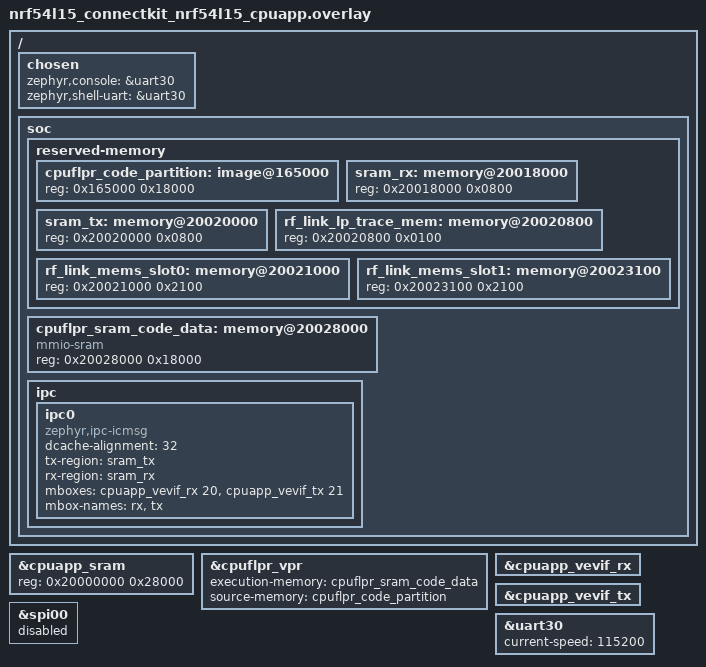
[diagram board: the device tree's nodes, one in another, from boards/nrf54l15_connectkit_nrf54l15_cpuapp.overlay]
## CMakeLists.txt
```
#
# Copyright (c) 2018 Nordic Semiconductor
# Copyright (c) 2016-2025 Makerdiary <https://makerdiary.com>
#
# SPDX-License-Identifier: LicenseRef-Nordic-5-Clause
#
cmake_minimum_required(VERSION 3.20.0)

find_package(Zephyr REQUIRED HINTS $ENV{ZEPHYR_BASE})
project(rf_link_tx)

# NORDIC SDK APP START
target_sources(app PRIVATE
  src/fatal_diag.c
  src/main.c
  src/debug_uart.c
  src/ipc_bridge.c
  src/radio_link.c
)

target_include_directories(app PRIVATE
  src
  ${CMAKE_CURRENT_SOURCE_DIR}/../rf_link_common
)

# NORDIC SDK APP END
```

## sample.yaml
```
sample:
  name: RF Link TX
tests:
  application.rf_link_tx:
    sysbuild: true
    build_only: true
    integration_platforms:
      - nrf54l15_connectkit/nrf54l15/cpuapp
```

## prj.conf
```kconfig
CONFIG_SERIAL=y
CONFIG_CONSOLE=y
CONFIG_UART_CONSOLE=n

CONFIG_MBOX=y
CONFIG_IPC_SERVICE=y
CONFIG_IPC_SERVICE_BACKEND_ICMSG=y
CONFIG_ASSERT=y
CONFIG_CRC=y

CONFIG_ESB=y
CONFIG_ESB_MAX_PAYLOAD_LENGTH=224
CONFIG_ESB_TX_FIFO_SIZE=16
CONFIG_ESB_RX_FIFO_SIZE=16
CONFIG_CLOCK_CONTROL=y
CONFIG_NRFX_DPPI10=y

CONFIG_MAIN_STACK_SIZE=4096
CONFIG_IPC_SERVICE_BACKEND_ICMSG_WQ_STACK_SIZE=4096
CONFIG_PBUF_RX_READ_BUF_SIZE=256
```

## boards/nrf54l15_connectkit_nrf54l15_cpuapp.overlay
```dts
/ {
	chosen {
		zephyr,console = &uart30;
		zephyr,shell-uart = &uart30;
	};

	soc {
		reserved-memory {
			#address-cells = <1>;
			#size-cells = <1>;
			ranges;

			/* FLPR code partition */
			cpuflpr_code_partition: image@165000 {
				reg = <0x165000 0x18000>; /* 96 KB */
			};

			/* ICMSG shared memory: HP receives here */
			sram_rx: memory@20018000 {
				reg = <0x20018000 0x0800>;
			};

			/* ICMSG shared memory: HP transmits here */
			sram_tx: memory@20020000 {
				reg = <0x20020000 0x0800>;
			};

			/* LP runtime trace shared with HP for diagnostics */
			rf_link_lp_trace_mem: memory@20020800 {
				reg = <0x20020800 0x0100>;
			};

			/* Ping-pong MEMS batches written by FLPR and read by CPUAPP. */
			rf_link_mems_slot0: memory@20021000 {
				reg = <0x20021000 0x2100>;
			};

			rf_link_mems_slot1: memory@20023100 {
				reg = <0x20023100 0x2100>;
			};
		};

		/* FLPR execution SRAM */
		cpuflpr_sram_code_data: memory@20028000 {
			compatible = "mmio-sram";
			reg = <0x20028000 0x18000>; /* 96 KB */
			#address-cells = <1>;
			#size-cells = <1>;
			ranges = <0x0 0x20028000 0x18000>;
		};

		ipc {
			ipc0: ipc0 {
				compatible = "zephyr,ipc-icmsg";
				dcache-alignment = <32>;
				tx-region = <&sram_tx>;
				rx-region = <&sram_rx>;
				mboxes = <&cpuapp_vevif_rx 20>, <&cpuapp_vevif_tx 21>;
				mbox-names = "rx", "tx";
				status = "okay";
			};
		};
	};
};

&cpuapp_sram {
	reg = <0x20000000 0x28000>; /* 160 KB */
	ranges = <0x0 0x20000000 0x28000>;
};

&cpuflpr_vpr {
	status = "okay";
	execution-memory = <&cpuflpr_sram_code_data>;
	source-memory = <&cpuflpr_code_partition>;
};

&cpuapp_vevif_rx {
	status = "okay";
};

&cpuapp_vevif_tx {
	status = "okay";
};

/* SPIM00 is owned by FLPR while it acquires IIM-42352 samples. */
&spi00 {
	status = "disabled";
};

&uart30 {
	status = "okay";
	current-speed = <115200>;
	/delete-property/ hw-flow-control;
};
```

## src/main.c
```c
#include <errno.h>
#include <stdint.h>
#include <string.h>
#include <zephyr/cache.h>
#include <zephyr/app_version.h>
#include <zephyr/kernel.h>
#include <zephyr/sys/barrier.h>
#include <zephyr/sys/crc.h>

#include "debug_uart.h"
#include "ipc_bridge.h"
#include "lp_trace.h"
#include "mems_batch.h"
#include "radio_link.h"
#include "rf_link_proto.h"

#define BATCH_RELEASE_TIMEOUT_MS 20u
#define BATCH_RELEASE_RETRIES    3u

struct batch_tx_stats {
	uint32_t batches_received;
	uint32_t batches_sent;
	uint32_t batches_failed;
	uint32_t batch_bad_header;
	uint32_t batch_bad_crc;
	uint32_t frames_attempted;
	uint32_t frames_sent;
	uint32_t frames_failed;
	uint32_t samples_sent;
	uint32_t release_errors;
};

static struct batch_tx_stats batch_stats;
static uint16_t rf_seq;
static bool radio_ready;

static void print_boot_line(void)
{
	debug_uart_puts("\r\nrf_link_tx HP started");
	debug_uart_crlf();
	debug_uart_puts("mode=MEMS_BATCH_ESB_PTX,phy=");
	debug_uart_puts(radio_link_phy_label());
	debug_uart_puts(",ack=");
	debug_uart_puts(RF_LINK_NOACK_STREAM ? "noack" : "ack");
	debug_uart_puts(",channel=");
	debug_uart_u32(RF_LINK_CHANNEL);
	debug_uart_puts(",pipe=");
	debug_uart_u32(RF_LINK_PIPE);
	debug_uart_puts(",prefix=0x54,fw=");
	debug_uart_puts(STRINGIFY(APP_BUILD_VERSION));
	debug_uart_puts(",batch_samples=");
	debug_uart_u32(RF_LINK_MEMS_BATCH_SAMPLE_COUNT);
	debug_uart_puts(",samples_per_frame=");
	debug_uart_u32(RF_LINK_FRAME_SAMPLE_COUNT);
	debug_uart_puts(",sample_hz=");
	debug_uart_u32(RF_LINK_TARGET_SAMPLE_HZ);
	debug_uart_crlf();
}

static void print_status(void)
{
	struct ipc_bridge_stats ipc_stats;
	struct rf_link_lp_trace lp_trace;
	struct radio_link_stats radio_stats = {0};
	bool have_lp_trace;

	ipc_bridge_stats_get(&ipc_stats);
	if (radio_ready) {
		radio_link_stats_get(&radio_stats);
	}
	have_lp_trace = rf_link_lp_trace_snapshot(&lp_trace);

	debug_uart_puts("TX stat batches_rx=");
	debug_uart_u32(batch_stats.batches_received);
	debug_uart_puts(" batches_ok=");
	debug_uart_u32(batch_stats.batches_sent);
	debug_uart_puts(" batch_bad_hdr=");
	debug_uart_u32(batch_stats.batch_bad_header);
	debug_uart_puts(" batches_fail=");
	debug_uart_u32(batch_stats.batches_failed);
	debug_uart_puts(" batch_bad_crc=");
	debug_uart_u32(batch_stats.batch_bad_crc);
	debug_uart_puts(" frames_try=");
	debug_uart_u32(batch_stats.frames_attempted);
	debug_uart_puts(" frames_ok=");
	debug_uart_u32(batch_stats.frames_sent);
	debug_uart_puts(" frames_fail=");
	debug_uart_u32(batch_stats.frames_failed);
	debug_uart_puts(" samples_ok=");
	debug_uart_u32(batch_stats.samples_sent);
	debug_uart_puts(" ipc_bad=");
	debug_uart_u32(ipc_stats.bad_size + ipc_stats.bad_message);
	debug_uart_puts(" ipc_drop=");
	debug_uart_u32(ipc_stats.queue_drop);
	debug_uart_puts(" release_err=");
	debug_uart_u32(batch_stats.release_errors + ipc_stats.release_fail);
	debug_uart_puts(" rf_ok=");
	debug_uart_u32(radio_stats.tx_ok);
	debug_uart_puts(" rf_fail=");
	debug_uart_u32(radio_stats.tx_failed);
	debug_uart_puts(" rf_timeout=");
	debug_uart_u32(radio_stats.tx_timeout);
	debug_uart_puts(" mac_avg_us=");
	debug_uart_u32(radio_stats.mac_latency_avg_us);
	debug_uart_puts(" lp_stage=");
	debug_uart_u32(have_lp_trace ? lp_trace.stage : 0u);
	debug_uart_puts(" lp_batches=");
	debug_uart_u32(have_lp_trace ? lp_trace.batches_ready : 0u);
	debug_uart_puts(" lp_samples=");
	debug_uart_u32(have_lp_trace ? lp_trace.sensor_samples : 0u);
	debug_uart_puts(" lp_irq=");
	debug_uart_u32(have_lp_trace ? lp_trace.sensor_irq_count : 0u);
	debug_uart_puts(" lp_poll=");
	debug_uart_u32(have_lp_trace ? lp_trace.sensor_poll_fallbacks : 0u);
	debug_uart_puts(" lp_malformed=");
	debug_uart_u32(have_lp_trace ? lp_trace.sensor_malformed : 0u);
	debug_uart_puts(" lp_io_err=");
	debug_uart_u32(have_lp_trace ? lp_trace.sensor_io_errors : 0u);
	debug_uart_puts(" lp_fifo_ovf=");
	debug_uart_u32(have_lp_trace ? lp_trace.fifo_overflows : 0u);
	debug_uart_puts(" lp_slot_wait=");
	debug_uart_u32(have_lp_trace ? lp_trace.slot_waits : 0u);
	debug_uart_puts(" lp_fatal=");
	debug_uart_u32(have_lp_trace ? lp_trace.fatal_count : 0u);
	debug_uart_puts(" lp_fatal_reason=");
	debug_uart_u32(have_lp_trace ? lp_trace.fatal_reason : 0u);
	debug_uart_crlf();
}

static int ensure_radio_ready(void)
{
	int ret;

	if (radio_ready) {
		return 0;
	}

	ret = radio_link_init();
	if (ret == 0) {
		radio_ready = true;
		debug_uart_puts("radio ready after first MEMS batch");
		debug_uart_crlf();
	}

	return ret;
}

static bool batch_header_is_valid(
	const volatile struct rf_link_mems_batch *batch,
	const struct rf_link_ipc_message *message)
{
	return batch != NULL && message != NULL &&
	       batch->magic == RF_LINK_MEMS_BATCH_MAGIC &&
	       batch->version == RF_LINK_MEMS_BATCH_VERSION &&
	       batch->slot_index == message->slot_index &&
	       batch->batch_seq == message->batch_seq &&
	       batch->sample_count == RF_LINK_MEMS_BATCH_SAMPLE_COUNT &&
	       batch->sample_crc32 == message->sample_crc32;
}

static int transmit_batch(const struct rf_link_ipc_message *message)
{
	volatile struct rf_link_mems_batch *batch;
	const int16_t *samples;
	uint32_t crc;
	uint32_t offset = 0u;
	int first_error = 0;
	int ret;

	batch = rf_link_mems_batch_slot(message->slot_index);
	if (batch == NULL) {
		batch_stats.batch_bad_header++;
		return -EINVAL;
	}

	(void)sys_cache_data_invd_range((void *)(uintptr_t)batch, sizeof(*batch));
	barrier_dmem_fence_full();
	batch_stats.batches_received++;

	if (!batch_header_is_valid(batch, message)) {
		batch_stats.batch_bad_header++;
		return -EBADMSG;
	}

	samples = (const int16_t *)(uintptr_t)&batch->samples[0];
	crc = crc32_ieee((const uint8_t *)samples, sizeof(batch->samples));
	if (crc != message->sample_crc32) {
		batch_stats.batch_bad_crc++;
		return -EBADMSG;
	}

	ret = ensure_radio_ready();
	if (ret != 0) {
		return ret;
	}

	while (offset < RF_LINK_MEMS_BATCH_SAMPLE_COUNT) {
		struct rf_frame frame = {0};
		uint32_t remaining = RF_LINK_MEMS_BATCH_SAMPLE_COUNT - offset;
		uint32_t frame_samples = MIN(remaining, RF_LINK_FRAME_SAMPLE_COUNT);

		frame.magic = RF_LINK_MAGIC;
		frame.seq = rf_seq++;
		frame.sample_count = (uint16_t)frame_samples;
		frame.flags = RF_LINK_FRAME_FLAGS_MEMS;
		if (offset == 0u) {
			frame.flags |= RF_LINK_FRAME_FLAGS_BATCH_START;
		}
		if (frame_samples == remaining) {
			frame.flags |= RF_LINK_FRAME_FLAGS_BATCH_END;
		}
		frame.timestamp_ms = batch->capture_start_ms +
			(uint32_t)(((uint64_t)offset * 1000u) /
				   RF_LINK_TARGET_SAMPLE_HZ);
		memcpy(frame.samples, &samples[offset],
		       frame_samples * sizeof(frame.samples[0]));

		batch_stats.frames_attempted++;
		ret = radio_link_send_frame(&frame, K_MSEC(5));
		if (ret == 0) {
			batch_stats.frames_sent++;
			batch_stats.samples_sent += frame_samples;
		} else {
			batch_stats.frames_failed++;
			if (first_error == 0) {
				first_error = ret;
			}
		}
		offset += frame_samples;
	}

	if (first_error == 0) {
		batch_stats.batches_sent++;
	} else {
		batch_stats.batches_failed++;
	}

	return first_error;
}

static void release_batch(const struct rf_link_ipc_message *message)
{
	int ret = -EIO;

	for (uint32_t attempt = 0u; attempt < BATCH_RELEASE_RETRIES; attempt++) {
		ret = ipc_bridge_release_batch(message->slot_index, message->batch_seq,
					       K_MSEC(BATCH_RELEASE_TIMEOUT_MS));
		if (ret == 0) {
			return;
		}
	}

	batch_stats.release_errors++;
}

int main(void)
{
	struct rf_link_ipc_message message;
	uint32_t last_status_ms;
	int ret;

	(void)debug_uart_init();
	print_boot_line();
	memset(&batch_stats, 0, sizeof(batch_stats));
	rf_seq = 0u;
	radio_ready = false;

	ret = ipc_bridge_init();
	if (ret != 0) {
		debug_uart_puts("ipc init failed err=");
		debug_uart_i32(ret);
		debug_uart_crlf();
		return ret;
	}

	ret = ipc_bridge_wait_bound(K_FOREVER);
	if (ret != 0) {
		debug_uart_puts("ipc bind failed err=");
		debug_uart_i32(ret);
		debug_uart_crlf();
		return ret;
	}

	debug_uart_puts("LP IPC bound; CPUAPP blocking until a 4096-sample batch is ready");
	debug_uart_crlf();
	last_status_ms = k_uptime_get_32();

	while (1) {
		ret = ipc_bridge_wait_batch(&message, K_FOREVER);
		if (ret != 0) {
			continue;
		}

		ret = transmit_batch(&message);
		if (ret != 0) {
			debug_uart_puts("batch rejected/failed seq=");
			debug_uart_u32(message.batch_seq);
			debug_uart_puts(" err=");
			debug_uart_i32(ret);
			debug_uart_crlf();
		}
		release_batch(&message);

		if ((uint32_t)(k_uptime_get_32() - last_status_ms) >=
		    RF_LINK_STATUS_PERIOD_MS) {
			print_status();
			last_status_ms = k_uptime_get_32();
		}
	}
}
```

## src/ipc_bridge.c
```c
#include "ipc_bridge.h"

#include <errno.h>
#include <string.h>
#include <zephyr/device.h>
#include <zephyr/devicetree.h>
#include <zephyr/ipc/ipc_service.h>
#include <zephyr/sys/atomic.h>

#define IPC_NODE DT_NODELABEL(ipc0)

#if !DT_NODE_HAS_STATUS(IPC_NODE, okay)
#error "ipc0 is not enabled in devicetree"
#endif

static K_SEM_DEFINE(bound_sem, 0, 1);
K_MSGQ_DEFINE(batch_msgq, sizeof(struct rf_link_ipc_message),
	      RF_LINK_MEMS_BATCH_SLOT_COUNT, 4);

static struct ipc_ept hp_ept;
static atomic_t received;
static atomic_t bad_size;
static atomic_t bad_message;
static atomic_t queued;
static atomic_t queue_drop;
static atomic_t releases;
static atomic_t release_fail;

static void bridge_bound(void *priv)
{
	ARG_UNUSED(priv);
	k_sem_give(&bound_sem);
}

static void bridge_received(const void *data, size_t len, void *priv)
{
	struct rf_link_ipc_message message;
	int ret;

	ARG_UNUSED(priv);
	atomic_inc(&received);

	if (data == NULL || len != sizeof(message)) {
		atomic_inc(&bad_size);
		return;
	}

	memcpy(&message, data, sizeof(message));
	if (message.magic != RF_LINK_IPC_MAGIC ||
	    message.version != RF_LINK_IPC_VERSION ||
	    message.type != RF_LINK_IPC_BATCH_READY ||
	    message.slot_index >= RF_LINK_MEMS_BATCH_SLOT_COUNT ||
	    message.sample_count != RF_LINK_MEMS_BATCH_SAMPLE_COUNT) {
		atomic_inc(&bad_message);
		return;
	}

	ret = k_msgq_put(&batch_msgq, &message, K_NO_WAIT);
	if (ret == 0) {
		atomic_inc(&queued);
	} else {
		atomic_inc(&queue_drop);
	}
}

static void bridge_error(const char *message, void *priv)
{
	ARG_UNUSED(message);
	ARG_UNUSED(priv);
}

static const struct ipc_ept_cfg hp_ept_cfg = {
	.name = "rf_link_ept",
	.cb = {
		.bound = bridge_bound,
		.received = bridge_received,
		.error = bridge_error,
	},
};

int ipc_bridge_init(void)
{
	const struct device *ipc0 = DEVICE_DT_GET(IPC_NODE);
	int ret;

	if (!device_is_ready(ipc0)) {
		return -ENODEV;
	}

	k_msgq_purge(&batch_msgq);
	atomic_clear(&received);
	atomic_clear(&bad_size);
	atomic_clear(&bad_message);
	atomic_clear(&queued);
	atomic_clear(&queue_drop);
	atomic_clear(&releases);
	atomic_clear(&release_fail);

	ret = ipc_service_open_instance(ipc0);
	if (ret < 0 && ret != -EALREADY) {
		return ret;
	}

	return ipc_service_register_endpoint(ipc0, &hp_ept, &hp_ept_cfg);
}

int ipc_bridge_wait_bound(k_timeout_t timeout)
{
	return k_sem_take(&bound_sem, timeout);
}

int ipc_bridge_wait_batch(struct rf_link_ipc_message *message,
			  k_timeout_t timeout)
{
	if (message == NULL) {
		return -EINVAL;
	}

	return k_msgq_get(&batch_msgq, message, timeout);
}

int ipc_bridge_release_batch(uint32_t slot_index, uint32_t batch_seq,
			     k_timeout_t timeout)
{
	struct rf_link_ipc_message message = {
		.magic = RF_LINK_IPC_MAGIC,
		.version = RF_LINK_IPC_VERSION,
		.type = RF_LINK_IPC_BATCH_RELEASE,
		.slot_index = slot_index,
		.batch_seq = batch_seq,
	};
	k_timepoint_t end = sys_timepoint_calc(timeout);
	int ret;

	do {
		ret = ipc_service_send(&hp_ept, &message, sizeof(message));
		if (ret == 0 || ret == (int)sizeof(message)) {
			atomic_inc(&releases);
			return 0;
		}

		if (ret != -ENOMEM && ret != -EAGAIN &&
		    ret != -EBUSY && ret != -ENOBUFS) {
			break;
		}
		k_sleep(K_USEC(50));
	} while (K_TIMEOUT_EQ(timeout, K_FOREVER) || !sys_timepoint_expired(end));

	atomic_inc(&release_fail);
	return ret;
}

void ipc_bridge_stats_get(struct ipc_bridge_stats *stats)
{
	if (stats == NULL) {
		return;
	}

	stats->received = (uint32_t)atomic_get(&received);
	stats->bad_size = (uint32_t)atomic_get(&bad_size);
	stats->bad_message = (uint32_t)atomic_get(&bad_message);
	stats->queued = (uint32_t)atomic_get(&queued);
	stats->queue_drop = (uint32_t)atomic_get(&queue_drop);
	stats->releases = (uint32_t)atomic_get(&releases);
	stats->release_fail = (uint32_t)atomic_get(&release_fail);
}
```

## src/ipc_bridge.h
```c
#ifndef RF_LINK_IPC_BRIDGE_H_
#define RF_LINK_IPC_BRIDGE_H_

#include <stdint.h>
#include <zephyr/kernel.h>

#include "mems_batch.h"

struct ipc_bridge_stats {
	uint32_t received;
	uint32_t bad_size;
	uint32_t bad_message;
	uint32_t queued;
	uint32_t queue_drop;
	uint32_t releases;
	uint32_t release_fail;
};

int ipc_bridge_init(void);
int ipc_bridge_wait_bound(k_timeout_t timeout);
int ipc_bridge_wait_batch(struct rf_link_ipc_message *message,
			  k_timeout_t timeout);
int ipc_bridge_release_batch(uint32_t slot_index, uint32_t batch_seq,
			     k_timeout_t timeout);
void ipc_bridge_stats_get(struct ipc_bridge_stats *stats);

#endif /* RF_LINK_IPC_BRIDGE_H_ */
```

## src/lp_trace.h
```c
#ifndef RF_LINK_LP_TRACE_H_
#define RF_LINK_LP_TRACE_H_

#include <stdbool.h>
#include <stdint.h>
#include <zephyr/devicetree.h>
#include <zephyr/kernel.h>

#define RF_LINK_LP_TRACE_MAGIC   0x4c505452u
#define RF_LINK_LP_TRACE_VERSION 1u             //默认是 deadline 模式，要改回相对 k_sleep() 版本置0

#define RF_LINK_LP_TRACE_NODE DT_NODELABEL(rf_link_lp_trace_mem)

#if !DT_NODE_HAS_STATUS(RF_LINK_LP_TRACE_NODE, okay)
#error "rf_link_lp_trace_mem is not enabled in devicetree"
#endif

enum rf_link_lp_stage {
	RF_LINK_LP_STAGE_RESET = 0u,
	RF_LINK_LP_STAGE_BOOT = 1u,
	RF_LINK_LP_STAGE_IPC_READY = 2u,
	RF_LINK_LP_STAGE_IPC_BOUND = 3u,
	RF_LINK_LP_STAGE_RUN = 4u,
};

struct rf_link_lp_trace {
	uint32_t magic;
	uint32_t version;
	uint32_t boot_count;
	uint32_t fatal_count;
	uint32_t stage;
	uint32_t loop_count;
	uint32_t last_seq;
	uint32_t last_uptime_ms;
	uint32_t fatal_reason;
	int32_t last_send_ret;
	uint32_t ipc_sent;
	uint32_t ipc_busy;
	uint32_t ipc_failed;
};

static inline volatile struct rf_link_lp_trace *rf_link_lp_trace_ptr(void)
{
	return (volatile struct rf_link_lp_trace *)(uintptr_t)
		DT_REG_ADDR(RF_LINK_LP_TRACE_NODE);
}

static inline void rf_link_lp_trace_boot(void)
{
	volatile struct rf_link_lp_trace *trace = rf_link_lp_trace_ptr();
	uint32_t boot_count = 1u;

	if (trace->magic == RF_LINK_LP_TRACE_MAGIC &&
	    trace->version == RF_LINK_LP_TRACE_VERSION) {
		boot_count = trace->boot_count + 1u;
	}

	trace->magic = RF_LINK_LP_TRACE_MAGIC;
	trace->version = RF_LINK_LP_TRACE_VERSION;
	trace->boot_count = boot_count;
	if (boot_count == 1u) {
		trace->fatal_count = 0u;
	}
	trace->stage = RF_LINK_LP_STAGE_BOOT;
	trace->loop_count = 0u;
	trace->last_seq = 0u;
	trace->last_uptime_ms = k_uptime_get_32();
	trace->fatal_reason = 0u;
	trace->last_send_ret = 0;
	trace->ipc_sent = 0u;
	trace->ipc_busy = 0u;
	trace->ipc_failed = 0u;
}

static inline void rf_link_lp_trace_set_stage(uint32_t stage)
{
	volatile struct rf_link_lp_trace *trace = rf_link_lp_trace_ptr();

	trace->stage = stage;
	trace->last_uptime_ms = k_uptime_get_32();
}

static inline void rf_link_lp_trace_note_loop(uint16_t seq)
{
	volatile struct rf_link_lp_trace *trace = rf_link_lp_trace_ptr();

	trace->stage = RF_LINK_LP_STAGE_RUN;
	trace->loop_count++;
	trace->last_seq = seq;
	trace->last_uptime_ms = k_uptime_get_32();
}

static inline void rf_link_lp_trace_note_ipc(uint32_t sent, uint32_t busy,
					     uint32_t failed, int32_t last_ret)
{
	volatile struct rf_link_lp_trace *trace = rf_link_lp_trace_ptr();

	trace->ipc_sent = sent;
	trace->ipc_busy = busy;
	trace->ipc_failed = failed;
	trace->last_send_ret = last_ret;
	trace->last_uptime_ms = k_uptime_get_32();
}

static inline void rf_link_lp_trace_note_fatal(uint32_t reason)
{
	volatile struct rf_link_lp_trace *trace = rf_link_lp_trace_ptr();

	trace->fatal_count++;
	trace->fatal_reason = reason;
	trace->last_uptime_ms = k_uptime_get_32();
}

static inline bool rf_link_lp_trace_snapshot(struct rf_link_lp_trace *out)
{
	volatile struct rf_link_lp_trace *trace = rf_link_lp_trace_ptr();

	if (out == NULL) {
		return false;
	}

	out->magic = trace->magic;
	out->version = trace->version;
	out->boot_count = trace->boot_count;
	out->fatal_count = trace->fatal_count;
	out->stage = trace->stage;
	out->loop_count = trace->loop_count;
	out->last_seq = trace->last_seq;
	out->last_uptime_ms = trace->last_uptime_ms;
	out->fatal_reason = trace->fatal_reason;
	out->last_send_ret = trace->last_send_ret;
	out->ipc_sent = trace->ipc_sent;
	out->ipc_busy = trace->ipc_busy;
	out->ipc_failed = trace->ipc_failed;

	return out->magic == RF_LINK_LP_TRACE_MAGIC &&
	       out->version == RF_LINK_LP_TRACE_VERSION;
}

#endif /* RF_LINK_LP_TRACE_H_ */
```

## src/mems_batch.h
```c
#ifndef RF_LINK_MEMS_BATCH_H_
#define RF_LINK_MEMS_BATCH_H_

#include <stddef.h>
#include <stdint.h>
#include <zephyr/devicetree.h>
#include <zephyr/sys/util.h>

#include "rf_link_proto.h"

#define RF_LINK_MEMS_BATCH_MAGIC        0x4d424154u
#define RF_LINK_MEMS_BATCH_VERSION      1u
#define RF_LINK_MEMS_BATCH_SAMPLE_COUNT 4096u
#define RF_LINK_MEMS_BATCH_SLOT_COUNT   2u

#define RF_LINK_IPC_MAGIC               0x52464950u
#define RF_LINK_IPC_VERSION             1u

enum rf_link_ipc_message_type {
	RF_LINK_IPC_BATCH_READY = 1u,
	RF_LINK_IPC_BATCH_RELEASE = 2u,
};

struct rf_link_mems_batch {
	uint32_t magic;
	uint32_t version;
	uint32_t slot_index;
	uint32_t batch_seq;
	uint32_t sample_count;
	uint32_t capture_start_ms;
	uint32_t capture_end_ms;
	uint32_t sample_crc32;
	int16_t samples[RF_LINK_MEMS_BATCH_SAMPLE_COUNT];
} __aligned(32);

struct rf_link_ipc_message {
	uint32_t magic;
	uint32_t version;
	uint32_t type;
	uint32_t slot_index;
	uint32_t batch_seq;
	uint32_t sample_count;
	uint32_t sample_crc32;
};

#define RF_LINK_MEMS_SLOT0_NODE DT_NODELABEL(rf_link_mems_slot0)
#define RF_LINK_MEMS_SLOT1_NODE DT_NODELABEL(rf_link_mems_slot1)

#if !DT_NODE_HAS_STATUS(RF_LINK_MEMS_SLOT0_NODE, okay)
#error "rf_link_mems_slot0 is not enabled in devicetree"
#endif

#if !DT_NODE_HAS_STATUS(RF_LINK_MEMS_SLOT1_NODE, okay)
#error "rf_link_mems_slot1 is not enabled in devicetree"
#endif

BUILD_ASSERT(RF_LINK_MEMS_BATCH_SAMPLE_COUNT > RF_LINK_FRAME_SAMPLE_COUNT,
	     "MEMS batch must contain more than one radio frame");
BUILD_ASSERT(DT_REG_SIZE(RF_LINK_MEMS_SLOT0_NODE) >= sizeof(struct rf_link_mems_batch),
	     "MEMS shared slot 0 is too small");
BUILD_ASSERT(DT_REG_SIZE(RF_LINK_MEMS_SLOT1_NODE) >= sizeof(struct rf_link_mems_batch),
	     "MEMS shared slot 1 is too small");
BUILD_ASSERT((DT_REG_ADDR(RF_LINK_MEMS_SLOT0_NODE) % 32u) == 0u,
	     "MEMS shared slot 0 must be cache-line aligned");
BUILD_ASSERT((DT_REG_ADDR(RF_LINK_MEMS_SLOT1_NODE) % 32u) == 0u,
	     "MEMS shared slot 1 must be cache-line aligned");
BUILD_ASSERT(sizeof(struct rf_link_ipc_message) <= CONFIG_PBUF_RX_READ_BUF_SIZE,
	     "PBUF RX buffer is too small for the batch IPC descriptor");

static inline volatile struct rf_link_mems_batch *rf_link_mems_batch_slot(uint32_t index)
{
	uintptr_t address;

	if (index == 0u) {
		address = DT_REG_ADDR(RF_LINK_MEMS_SLOT0_NODE);
	} else if (index == 1u) {
		address = DT_REG_ADDR(RF_LINK_MEMS_SLOT1_NODE);
	} else {
		return NULL;
	}

	return (volatile struct rf_link_mems_batch *)address;
}

#endif /* RF_LINK_MEMS_BATCH_H_ */
```

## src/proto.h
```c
#ifndef RF_LINK_PROTO_H_
#define RF_LINK_PROTO_H_

#include <stdint.h>
#include <zephyr/sys/util.h>

#define RF_LINK_MAGIC              0xA55Au
#define RF_LINK_FRAME_SAMPLE_COUNT 96u
#define RF_LINK_FRAME_FLAGS_TEST   BIT(0)
#define RF_LINK_CHANNEL            40u
#define RF_LINK_TARGET_SAMPLE_HZ   50000u
#define RF_LINK_TX_PERIOD_US       ((RF_LINK_FRAME_SAMPLE_COUNT * 1000000u) / \
				    RF_LINK_TARGET_SAMPLE_HZ)
#define RF_LINK_STATUS_PERIOD_MS   1000u
#define RF_LINK_NOACK_STREAM       1u
#define RF_LINK_LP_START_DELAY_MS  0u
#define RF_LINK_LP_WARMUP_FRAMES   16u
#define RF_LINK_LP_WARMUP_PERIOD_MS 10u
#define RF_LINK_LP_IPC_SEND_TIMEOUT_MS 5u
#define RF_LINK_LP_USE_ABSOLUTE_PACING 1u

struct rf_frame {
	uint16_t magic;
	uint16_t seq;
	uint16_t sample_count;
	uint16_t flags;
	uint32_t timestamp_ms;
	int16_t samples[RF_LINK_FRAME_SAMPLE_COUNT];
} __packed;

#define RF_LINK_FRAME_WIRE_SIZE sizeof(struct rf_frame)

BUILD_ASSERT(RF_LINK_FRAME_WIRE_SIZE == 204u,
	     "rf_frame wire size must stay fixed for this RF protocol revision");
BUILD_ASSERT(CONFIG_PBUF_RX_READ_BUF_SIZE >= RF_LINK_FRAME_WIRE_SIZE,
	     "PBUF RX buffer must be large enough for rf_frame IPC payloads");
BUILD_ASSERT(((RF_LINK_FRAME_SAMPLE_COUNT * 1000000u) %
	      RF_LINK_TARGET_SAMPLE_HZ) == 0u,
	     "RF_LINK_TX_PERIOD_US must be an integer number of microseconds");

#endif /* RF_LINK_PROTO_H_ */
```

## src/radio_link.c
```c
#include "radio_link.h"

#include <errno.h>
#include <string.h>
#include <zephyr/device.h>
#include <zephyr/devicetree.h>
#include <zephyr/drivers/clock_control.h>
#include <zephyr/drivers/clock_control/nrf_clock_control.h>
#include <zephyr/spinlock.h>
#include <zephyr/sys/atomic.h>
#include <esb.h>
#include <nrf.h>
#include <nrf_erratas.h>

#if defined(CONFIG_CLOCK_CONTROL_NRF2)
#include <hal/nrf_lrcconf.h>
#endif

#if NRF54L_ERRATA_20_PRESENT
#include <hal/nrf_power.h>
#endif

#if defined(NRF54LM20A_ENGA_XXAA)
#include <hal/nrf_clock.h>
#endif

BUILD_ASSERT(RF_LINK_FRAME_WIRE_SIZE <= CONFIG_ESB_MAX_PAYLOAD_LENGTH,
	     "CONFIG_ESB_MAX_PAYLOAD_LENGTH is too small for rf_frame");

#if defined(RADIO_MODE_MODE_Nrf_4Mbit_0BT6)
#define RF_LINK_ESB_BITRATE ESB_BITRATE_4MBPS
#define RF_LINK_PHY_LABEL   "4M"
#else
#define RF_LINK_ESB_BITRATE ESB_BITRATE_2MBPS
#define RF_LINK_PHY_LABEL   "2M"
#endif

static K_SEM_DEFINE(tx_done_sem, 0, 1);

static atomic_t tx_ok;
static atomic_t tx_failed;
static atomic_t tx_timeout;
static atomic_t tx_errors;
static atomic_t last_attempts;
static volatile int last_tx_result;

static struct k_spinlock latency_lock;
static uint32_t latency_count;
static uint32_t latency_last_us;
static uint32_t latency_min_us = UINT32_MAX;
static uint32_t latency_max_us;
static uint64_t latency_sum_us;

static void latency_stats_update(uint32_t latency_us)
{
	k_spinlock_key_t key = k_spin_lock(&latency_lock);

	latency_last_us = latency_us;
	if (latency_us < latency_min_us) {
		latency_min_us = latency_us;
	}
	if (latency_us > latency_max_us) {
		latency_max_us = latency_us;
	}
	latency_sum_us += latency_us;
	latency_count++;

	k_spin_unlock(&latency_lock, key);
}

static void radio_event_handler(const struct esb_evt *event)
{
	switch (event->evt_id) {
	case ESB_EVENT_TX_SUCCESS:
		last_tx_result = 0;
		atomic_inc(&tx_ok);
		atomic_set(&last_attempts, (atomic_val_t)event->tx_attempts);
		k_sem_give(&tx_done_sem);
		break;
	case ESB_EVENT_TX_FAILED:
		last_tx_result = -EIO;
		atomic_inc(&tx_failed);
		atomic_set(&last_attempts, (atomic_val_t)event->tx_attempts);
		k_sem_give(&tx_done_sem);
		break;
	case ESB_EVENT_RX_RECEIVED:
		break;
	}
}

#if defined(CONFIG_CLOCK_CONTROL_NRF)
static int clocks_start(void)
{
	int err;
	int res;
	struct onoff_manager *clk_mgr;
	struct onoff_client clk_cli;

	clk_mgr = z_nrf_clock_control_get_onoff(CLOCK_CONTROL_NRF_SUBSYS_HF);
	if (clk_mgr == NULL) {
		return -ENXIO;
	}

	sys_notify_init_spinwait(&clk_cli.notify);

	err = onoff_request(clk_mgr, &clk_cli);
	if (err < 0) {
		return err;
	}

	do {
		err = sys_notify_fetch_result(&clk_cli.notify, &res);
		if (err == 0 && res != 0) {
			return res;
		}
	} while (err != 0);

#if NRF54L_ERRATA_20_PRESENT
	if (nrf54l_errata_20()) {
		nrf_power_task_trigger(NRF_POWER, NRF_POWER_TASK_CONSTLAT);
	}
#endif

#if defined(NRF54LM20A_ENGA_XXAA)
	nrf_clock_task_trigger(NRF_CLOCK, NRF_CLOCK_TASK_PLLSTART);
#endif

	return 0;
}
#elif defined(CONFIG_CLOCK_CONTROL_NRF2)
static int clocks_start(void)
{
	int err;
	int res;
	const struct device *radio_clk_dev =
		DEVICE_DT_GET_OR_NULL(DT_CLOCKS_CTLR(DT_NODELABEL(radio)));
	struct onoff_client radio_cli;

	if (radio_clk_dev == NULL) {
		return -ENODEV;
	}

	nrf_lrcconf_poweron_force_set(NRF_LRCCONF010,
				      NRF_LRCCONF_POWER_DOMAIN_1, true);
	sys_notify_init_spinwait(&radio_cli.notify);

	err = nrf_clock_control_request(radio_clk_dev, NULL, &radio_cli);
	if (err < 0 && err != -EALREADY) {
		return err;
	}

	do {
		err = sys_notify_fetch_result(&radio_cli.notify, &res);
		if (err == 0 && res != 0) {
			return res;
		}
	} while (err == -EAGAIN);

	nrf_lrcconf_clock_always_run_force_set(NRF_LRCCONF000, 0, true);
	nrf_lrcconf_task_trigger(NRF_LRCCONF000, NRF_LRCCONF_TASK_CLKSTART_0);

	return 0;
}
#else
BUILD_ASSERT(false, "No Nordic clock control driver enabled");
#endif

int radio_link_init(void)
{
	static const uint8_t base_addr_0[4] = {0x52, 0x46, 0x4c, 0x31};
	static const uint8_t base_addr_1[4] = {0xc2, 0xc2, 0xc2, 0xc2};
	static const uint8_t addr_prefix[8] = {
		0x54, 0xc2, 0xc3, 0xc4, 0xc5, 0xc6, 0xc7, 0xc8
	};
	struct esb_config config = ESB_DEFAULT_CONFIG;
	int ret;

	ret = clocks_start();
	if (ret != 0) {
		return ret;
	}

	config.protocol = ESB_PROTOCOL_ESB_DPL;
	config.mode = ESB_MODE_PTX;
	config.bitrate = RF_LINK_ESB_BITRATE;
	config.crc = ESB_CRC_16BIT;
	config.event_handler = radio_event_handler;
	config.retransmit_delay = 600;
	config.retransmit_count = 0;
	config.payload_length = RF_LINK_FRAME_WIRE_SIZE;
	config.selective_auto_ack = true;
	config.tx_mode = ESB_TXMODE_AUTO;

	ret = esb_init(&config);
	if (ret != 0) {
		return ret;
	}

	ret = esb_set_address_length(5);
	if (ret != 0) {
		return ret;
	}

	ret = esb_set_base_address_0(base_addr_0);
	if (ret != 0) {
		return ret;
	}

	ret = esb_set_base_address_1(base_addr_1);
	if (ret != 0) {
		return ret;
	}

	ret = esb_set_prefixes(addr_prefix, ARRAY_SIZE(addr_prefix));
	if (ret != 0) {
		return ret;
	}

	ret = esb_set_rf_channel(RF_LINK_CHANNEL);
	if (ret != 0) {
		return ret;
	}

	return esb_flush_tx();
}

int radio_link_send_frame(const struct rf_frame *frame, k_timeout_t timeout)
{
	struct esb_payload payload = {0};
	uint32_t start_cycles;
	uint32_t elapsed_cycles;
	int ret;

	if (frame == NULL) {
		return -EINVAL;
	}

	payload.pipe = 0;
	payload.noack = RF_LINK_NOACK_STREAM ? true : false;
	payload.length = RF_LINK_FRAME_WIRE_SIZE;
	memcpy(payload.data, frame, sizeof(*frame));

	k_sem_reset(&tx_done_sem);
	last_tx_result = -EINPROGRESS;

	start_cycles = k_cycle_get_32();

	ret = esb_write_payload(&payload);
	if (ret != 0) {
		atomic_inc(&tx_errors);
		return ret;
	}

	ret = k_sem_take(&tx_done_sem, timeout);
	elapsed_cycles = k_cycle_get_32() - start_cycles;
	latency_stats_update(k_cyc_to_us_floor32(elapsed_cycles));

	if (ret != 0) {
		atomic_inc(&tx_timeout);
		(void)esb_flush_tx();
		return -ETIMEDOUT;
	}

	return last_tx_result;
}

void radio_link_stats_get(struct radio_link_stats *stats)
{
	k_spinlock_key_t key;

	if (stats == NULL) {
		return;
	}

	stats->tx_ok = (uint32_t)atomic_get(&tx_ok);
	stats->tx_failed = (uint32_t)atomic_get(&tx_failed);
	stats->tx_timeout = (uint32_t)atomic_get(&tx_timeout);
	stats->tx_errors = (uint32_t)atomic_get(&tx_errors);
	stats->last_attempts = (uint32_t)atomic_get(&last_attempts);

	key = k_spin_lock(&latency_lock);
	stats->mac_latency_count = latency_count;
	stats->mac_latency_last_us = latency_last_us;
	stats->mac_latency_min_us = (latency_count == 0u) ? 0u : latency_min_us;
	stats->mac_latency_avg_us = (latency_count == 0u) ? 0u :
				    (uint32_t)(latency_sum_us / latency_count);
	stats->mac_latency_max_us = latency_max_us;
	k_spin_unlock(&latency_lock, key);
}

const char *radio_link_phy_label(void)
{
	return RF_LINK_PHY_LABEL;
}
```

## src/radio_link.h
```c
#ifndef RF_LINK_RADIO_LINK_H_
#define RF_LINK_RADIO_LINK_H_

#include <stdint.h>
#include <zephyr/kernel.h>

#include "proto.h"

struct radio_link_stats {
	uint32_t tx_ok;
	uint32_t tx_failed;
	uint32_t tx_timeout;
	uint32_t tx_errors;
	uint32_t last_attempts;
	uint32_t mac_latency_count;
	uint32_t mac_latency_last_us;
	uint32_t mac_latency_min_us;
	uint32_t mac_latency_avg_us;
	uint32_t mac_latency_max_us;
};

int radio_link_init(void);
int radio_link_send_frame(const struct rf_frame *frame, k_timeout_t timeout);
void radio_link_stats_get(struct radio_link_stats *stats);
const char *radio_link_phy_label(void);

#endif /* RF_LINK_RADIO_LINK_H_ */
```

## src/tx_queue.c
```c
#include "tx_queue.h"

#include <errno.h>
#include <string.h>
#include <zephyr/sys/atomic.h>

#define TX_QUEUE_DEPTH 64

K_MSGQ_DEFINE(tx_frame_msgq, sizeof(struct rf_frame), TX_QUEUE_DEPTH, 4);

static struct rf_frame discard_frame;

static atomic_t pushed;
static atomic_t popped;
static atomic_t dropped;

void tx_queue_init(void)
{
	k_msgq_purge(&tx_frame_msgq);
	atomic_clear(&pushed);
	atomic_clear(&popped);
	atomic_clear(&dropped);
}

int tx_queue_submit(const struct rf_frame *frame)
{
	int ret;

	ret = k_msgq_put(&tx_frame_msgq, frame, K_NO_WAIT);
	if (ret == 0) {
		atomic_inc(&pushed);
		return 0;
	}

	if (ret == -ENOMSG) {
		ret = k_msgq_get(&tx_frame_msgq, &discard_frame, K_NO_WAIT);
		if (ret == 0) {
			atomic_inc(&dropped);
			ret = k_msgq_put(&tx_frame_msgq, frame, K_NO_WAIT);
			if (ret == 0) {
				atomic_inc(&pushed);
				return 0;
			}
		}
	}

	atomic_inc(&dropped);
	return ret;
}

int tx_queue_get(struct rf_frame *frame, k_timeout_t timeout)
{
	int ret = k_msgq_get(&tx_frame_msgq, frame, timeout);

	if (ret == 0) {
		atomic_inc(&popped);
	}

	return ret;
}

void tx_queue_stats_get(struct tx_queue_stats *stats)
{
	if (stats == NULL) {
		return;
	}

	stats->pushed = (uint32_t)atomic_get(&pushed);
	stats->popped = (uint32_t)atomic_get(&popped);
	stats->dropped = (uint32_t)atomic_get(&dropped);
}
```

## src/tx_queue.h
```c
#ifndef RF_LINK_TX_QUEUE_H_
#define RF_LINK_TX_QUEUE_H_

#include <stdint.h>
#include <zephyr/kernel.h>

#include "proto.h"

struct tx_queue_stats {
	uint32_t pushed;
	uint32_t popped;
	uint32_t dropped;
};

void tx_queue_init(void);
int tx_queue_submit(const struct rf_frame *frame);
int tx_queue_get(struct rf_frame *frame, k_timeout_t timeout);
void tx_queue_stats_get(struct tx_queue_stats *stats);

#endif /* RF_LINK_TX_QUEUE_H_ */
```
